# STM32H7P4xx register map
File version: 1.0
Registers are 32-bit, read-write, reset 0x0 unless marked. A register's access mark holds for its fields unless they carry their own. Offsets are from the block's base; [hi:lo] are bit positions.

## I2C1 — Inter-integrated Circuit Interface
Base 0x40005400
Same registers: I2C2 0x40005800, I2C3 0x40005C00
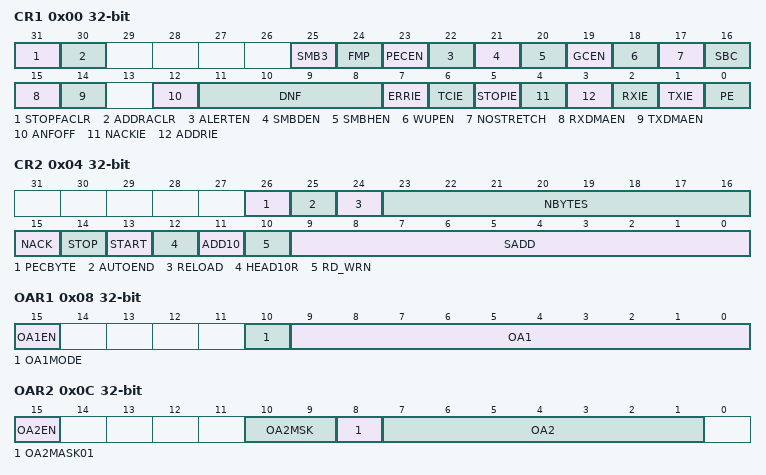
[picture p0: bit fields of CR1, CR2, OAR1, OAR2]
0x00 CR1 — I2C Control register 1
  [31] STOPFACLR — STOP detection flag (STOPF) automatic clear
  [30] ADDRACLR — Address match flag (ADDR) automatic clear
  [25] SMB3 — SMBus specification 3.0 I/O compliance enable
  [24] FMP — Fast-mode Plus 20 mA drive enable
  [23] PECEN — PEC enable
  [22] ALERTEN — SMBus alert enable
  [21] SMBDEN — SMBus device default address enable
  [20] SMBHEN — SMBus host address enable
  [19] GCEN — General call enable
  [18] WUPEN — Wake-up from Stop mode enable
  [17] NOSTRETCH — Clock stretching disable
  [16] SBC — Target byte control
  [15] RXDMAEN — DMA reception requests enable
  [14] TXDMAEN — DMA transmission requests enable
  [12] ANFOFF — Analog noise filter OFF
  [11:8] DNF — Digital noise filter
  [7] ERRIE — Error interrupts enable
  [6] TCIE — Transfer complete interrupt enable
  [5] STOPIE — STOP detection interrupt enable
  [4] NACKIE — Not acknowledge received interrupt enable
  [3] ADDRIE — Address match interrupt enable (target only)
  [2] RXIE — RX interrupt enable
  [1] TXIE — TX interrupt enable
  [0] PE — Peripheral enable
0x04 CR2 — I2C Control register 2
  [26] PECBYTE — Packet error checking byte
  [25] AUTOEND — Automatic end mode (controller mode)
  [24] RELOAD — NBYTES reload mode
  [23:16] NBYTES — Number of bytes
  [15] NACK — NACK generation (target mode)
  [14] STOP — STOP condition generation (master mode)
  [13] START — START condition generation
  [12] HEAD10R — 10-bit address header only read direction (controller receiver mode)
  [11] ADD10 — 10-bit addressing mode (controller mode)
  [10] RD_WRN — Transfer direction (controller mode)
  [9:0] SADD — Target address (controller mode)
0x08 OAR1 — I2C Own address 1 register
  [15] OA1EN — Own address 1 enable
  [10] OA1MODE — Own address 1 10-bit mode
  [9:0] OA1 — Interface own target address
0x0C OAR2 — I2C Own address 2 register
  [15] OA2EN — Own address 2 enable
  [10:9] OA2MSK — Own address 2 masks
  [8] OA2MASK01 — OA2[1] is masked, Only OA2[7:2] are compared
  [7:1] OA2 — Interface address
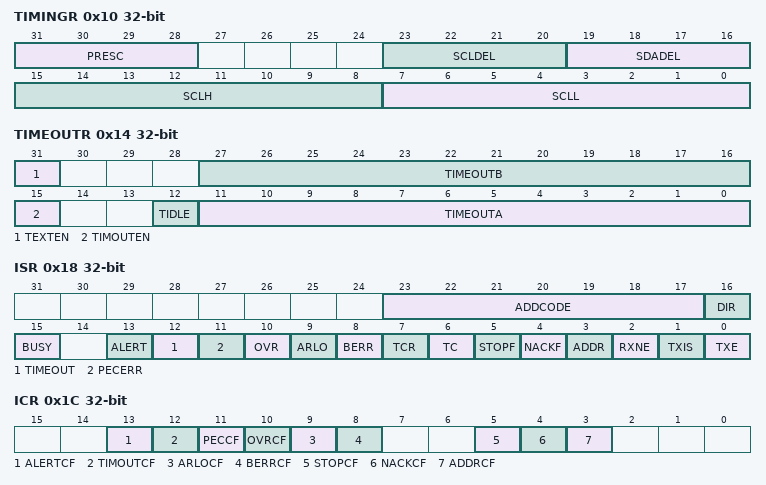
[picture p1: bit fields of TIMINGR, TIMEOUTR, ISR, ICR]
0x10 TIMINGR — I2C Timing register
  [31:28] PRESC — Timing prescaler
  [23:20] SCLDEL — Data setup time
  [19:16] SDADEL — Data hold time
  [15:8] SCLH — SCL high period (controller mode)
  [7:0] SCLL — SCL low period (controller mode)
0x14 TIMEOUTR — I2C Timeout register
  [31] TEXTEN — Extended clock timeout enable
  [27:16] TIMEOUTB — Bus timeout B
  [15] TIMOUTEN — Clock timeout enable
  [12] TIDLE — Idle clock timeout detection
  [11:0] TIMEOUTA — Bus timeout A
0x18 ISR — I2C Interrupt and status register
  [23:17] ADDCODE — Address match code (target mode)
  [16] DIR — Transfer direction (target mode)
  [15] BUSY — Bus busy
  [13] ALERT — SMBus alert
  [12] TIMEOUT — Timeout or t<sub>LOW</sub> detection flag
  [11] PECERR — PEC error in reception
  [10] OVR — Overrun/underrun (target mode)
  [9] ARLO — Arbitration lost
  [8] BERR — Bus error
  [7] TCR — Transfer complete reload
  [6] TC — Transfer complete (controller mode)
  [5] STOPF — STOP detection flag
  [4] NACKF — Not acknowledge received flag
  [3] ADDR — Address matched (target mode)
  [2] RXNE — Receive data register not empty (receivers)
  [1] TXIS — Transmit interrupt status (transmitters)
  [0] TXE — Transmit data register empty (transmitters)
0x1C ICR — I2C Interrupt clear register
  [13] ALERTCF — Alert flag clear
  [12] TIMOUTCF — Timeout flag clear
  [11] PECCF — PEC error flag clear
  [10] OVRCF — Overrun/underrun flag clear
  [9] ARLOCF — Arbitration lost flag clear
  [8] BERRCF — Bus error flag clear
  [5] STOPCF — STOP detection flag clear
  [4] NACKCF — Not acknowledge flag clear
  [3] ADDRCF — Address matched flag clear
0x20 PECR ro — I2C PEC register
  [7:0] PEC — Packet error checking register
0x24 RXDR ro — I2C Receive data register
  [7:0] RXDATA — 8-bit receive data
0x28 TXDR — I2C Transmit data register
  [7:0] TXDATA — 8-bit transmit data
